# CY8C5568AXI_060 register map
File version: 0.1
CY8C55
Registers are 8-bit, read-write, no defined reset value unless marked. A register's access mark holds for its fields unless they carry their own. Offsets are from the block's base; lines under a group give offsets from that group; [hi:lo] are bit positions; {n}, {i} and the like mark numbered series; 'fields as' and 'values as' point back to an identical list; <NAME> marks a mode.

## Memory map
0x400043A5 USBUART_1 size 0x1CF9 — USBFS
0x400043A8 IDAC8 size 0x17DB
0x40004614 ADC_SAR_1 size 0x158D — SAR ADC
0x40004616 ADC_SAR_0 size 0x158D — SAR ADC

## USBUART_1 — USBFS
Base 0x400043A5
0x00 USBUART_1_PM_ACT_CFG — Active Power Mode Configuration Register
0x10 USBUART_1_PM_STBY_CFG — Standby Power Mode Configuration Register
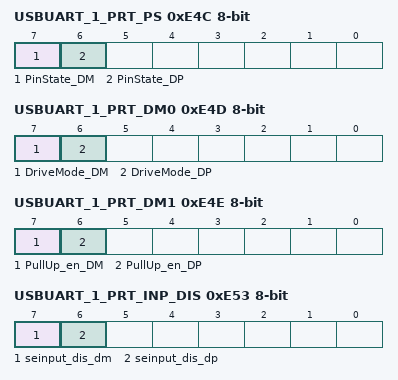
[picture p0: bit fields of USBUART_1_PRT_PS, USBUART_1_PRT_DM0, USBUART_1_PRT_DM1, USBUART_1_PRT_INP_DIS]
0xE4C USBUART_1_PRT_PS — Port Pin State Register
  [7] PinState_DM ro, [6] PinState_DP ro
0xE4D USBUART_1_PRT_DM0 — Port Drive Mode Register
  [7] DriveMode_DM, [6] DriveMode_DP
0xE4E USBUART_1_PRT_DM1 — Port Drive Mode Register
  [7] PullUp_en_DM, [6] PullUp_en_DP
0xE53 USBUART_1_PRT_INP_DIS — Input buffer disable override
  [7] seinput_dis_dm, [6] seinput_dis_dp
0x1C5B USBUART_1_EP0_DR0 — bmRequestType
0x1C5C USBUART_1_EP0_DR1 — bRequest
0x1C5D USBUART_1_EP0_DR2 — wValueLo
0x1C5E USBUART_1_EP0_DR3 — wValueHi
0x1C5F USBUART_1_EP0_DR4 — wIndexLo
0x1C60 USBUART_1_EP0_DR5 — wIndexHi
0x1C61 USBUART_1_EP0_DR6 — lengthLo
0x1C62 USBUART_1_EP0_DR7 — lengthHi
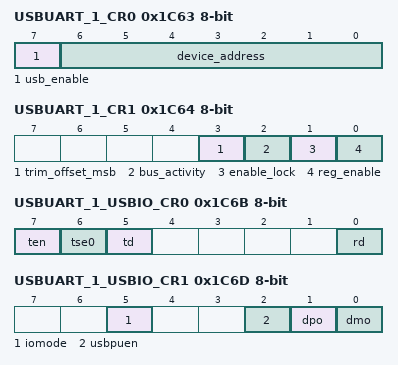
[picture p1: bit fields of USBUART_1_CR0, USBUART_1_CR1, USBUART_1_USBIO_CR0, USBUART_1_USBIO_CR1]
0x1C63 USBUART_1_CR0 — USB Control Register 0
  [7] usb_enable, [6:0] device_address ro
0x1C64 USBUART_1_CR1 — USB Control Register 1
  [3] trim_offset_msb, [2] bus_activity, [1] enable_lock, [0] reg_enable
{0x1C59+0x10*i} USBUART_1_SIE_EP{i}_CR0 (i=1..8) — The Endpoint{i} Control Register
0x1C6B USBUART_1_USBIO_CR0 — USBIO Control Register 0
  [7] ten, [6] tse0, [5] td, [0] rd ro
0x1C6D USBUART_1_USBIO_CR1 — USBIO Control Register 1
  [5] iomode, [2] usbpuen, [1] dpo ro, [0] dmo ro
0x1CE7 USBUART_1_BUF_SIZE — Dedicated Endpoint Buffer Size Register
0x1CE9 USBUART_1_EP_ACTIVE — Endpoint Active Indication Register
0x1CEA USBUART_1_EP_TYPE — Endpoint Type (IN/OUT) Indication
0x1CF8 USBUART_1_USB_CLK_EN — USB Block Clock Enable Register

## ADC_SAR_0 — SAR ADC
Base 0x40004616
0x00 SAR_TR0 — SAR trim register
{0x12F2+i} SAR_CSR{i} (i=0..6) — SAR status and control register {i}
0x1512 SAR_SW0 — SAR Analog Routing Register 0
{0x1512+i} SAR_SW{i} (i=2..4) — SAR Analog Routing Register {i}
0x1518 SAR_SW6 — SAR Analog Routing Register 6
0x1519 SAR_CLK — SAR Clock Selection Register
0x158C SAR_WRK 16-bit — SAR working register

## IDAC8
Base 0x400043A8
0x00 IDAC8_PM_ACT_CFG — Active Power Mode Configuration Register 8
  [3:0] en_dac — Enable DAC block(s). Populated subsystems are counted from the LSB.
0x10 IDAC8_PM_STBY_CFG — Standby Power Mode Configuration Register 8
  fields as IDAC8_PM_ACT_CFG
0x262 IDAC8_TR
  [7:0] tr — 8 Calibration bits
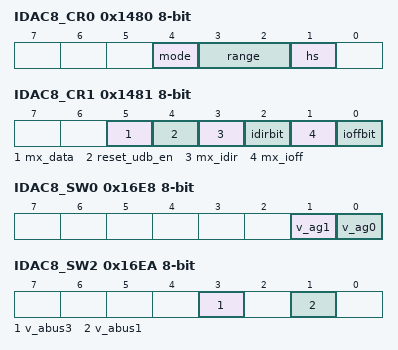
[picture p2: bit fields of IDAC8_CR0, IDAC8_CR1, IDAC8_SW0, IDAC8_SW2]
0x1480 IDAC8_CR0 — DAC Block Control Register 0
  [4] mode ro — Mode Bit
    0=DAC_MODE_V (voltage DAC); 1=DAC_MODE_I (current DAC)
  [3:2] range — Ranges for mode=0 (VDAC) and mode=1 (IDAC)
    0=DAC_RANGE_0 (x0=0V to 4*vref (1.024V); 0 to 31.875uA); 1=DAC_RANGE_1 (x1=0V to 16*vref (4.096V); 0 to 255uA); 2=DAC_RANGE_2 (x0=0V to 4*vref (1.024V); 0 to 2.040mA); 3=DAC_RANGE_3 (x1=0V to 16*vref (4.096V); not used)
  [1] hs — High Speed Bit
    0=DAC_HS_LOWPOWER (regular (low power)); 1=DAC_HS_HIGHSPEED (high speed (higher power))
0x1481 IDAC8_CR1 — DAC Block Control Register 1
  [5] mx_data — Select DATA source
    0=MX_DATA_REG (Select register source); 1=MX_DATA_UDB (Select UDB source)
  [4] reset_udb_en — DAC reset enable
    0=RESET_UDB_EN_DISABLE (Disable DAC Reset Source from UDB); 1=RESET_UDB_EN_ENABLE (Enable DAC Reset Source from UDB)
  [3] mx_idir — Mux selection for DAC current direction control
    0=MX_IDIR_REG (Register source idirbit selected); 1=MX_IDIR_UDB (UDB ictrl selected)
  [2] idirbit — register source for DAC current direction
  [1] mx_ioff — Mux selection for DAC current off control
    0=MX_IOFF_REG (Register source ioffbit selected); 1=MX_IOFF_UDB (UDB ictrl selected)
  [0] ioffbit — register source for DAC current off
0x16E8 IDAC8_SW0 — DAC Analog Routing Register 0
  [1] v_ag1 — Connect voltage output to analog global of same side
    0=AG_NC (not connected); 1=AG_CONNECTED (Connect to Analog Global)
  [0] v_ag0 — Connect voltage output to analog global of same side
    values as v_ag1
0x16EA IDAC8_SW2 — DAC Analog Routing Register 2
  [3] v_abus3 — Connect voltage output to analog (local) bus of the same side
    0=ABUS_NC (not connected); 1=ABUS_CONNECTED (Connect to Analog (local) Bus)
  [1] v_abus1 — Connect voltage output to analog (local) bus of the same side
    values as v_abus3
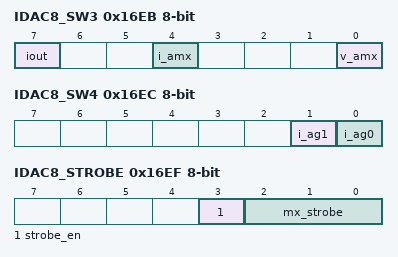
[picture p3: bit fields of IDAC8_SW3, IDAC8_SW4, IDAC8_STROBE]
0x16EB IDAC8_SW3 — DAC Analog Routing Register 3
  [7] iout — Connect current output to pad
    0=IOUT_NC (not connected); 1=IOUT_CONNECT (Connect to pad)
  [4] i_amx — Connect current output to Analog Mux Bus
    0=AMX_NC (not connected); 1=AMX_CONNECTED (Connect to AMUXBUS)
  [0] v_amx — Connect voltage output to Analog Mux Bus
    values as i_amx
0x16EC IDAC8_SW4 — DAC Analog Routing Register 4
  [1] i_ag1 — Connect current output to analog global of same side
    values as IDAC8_SW0.v_ag1
  [0] i_ag0 — Connect current output to analog global of same side
    values as IDAC8_SW0.v_ag1
0x16EF IDAC8_STROBE — DAC Strobe Register
  [3] strobe_en — Strobe gating control
    0=disable strobe; 1=enable strobe
  [2:0] mx_strobe — Strobe source selection
    0=MX_STROBE_BUSWRITE (Select bus write strobe source); 1=MX_STROBE_UDB_SRC (Select UDB strobe source); 2=MX_STROBE_NC_2 (NC); 3=MX_STROBE_NC_3 (NC); {v}=MX_STROBE_CLK_A{v-4}_DIG (Select clk_a{v-4}_dig) (v=4..7)
0x17DA IDAC8_D — DAC Data Register
  [7:0] data — 8 DAC Data bits

## ADC_SAR_1 — SAR ADC
Base 0x40004614
0x00 SAR_TR0 — SAR trim register
{0x12EC+i} SAR_CSR{i} (i=0..6) — SAR status and control register {i}
0x150C SAR_SW0 — SAR Analog Routing Register 0
{0x150C+i} SAR_SW{i} (i=2..4) — SAR Analog Routing Register {i}
0x1512 SAR_SW6 — SAR Analog Routing Register 6
0x1513 SAR_CLK — SAR Clock Selection Register
0x158C SAR_WRK 16-bit — SAR working register
